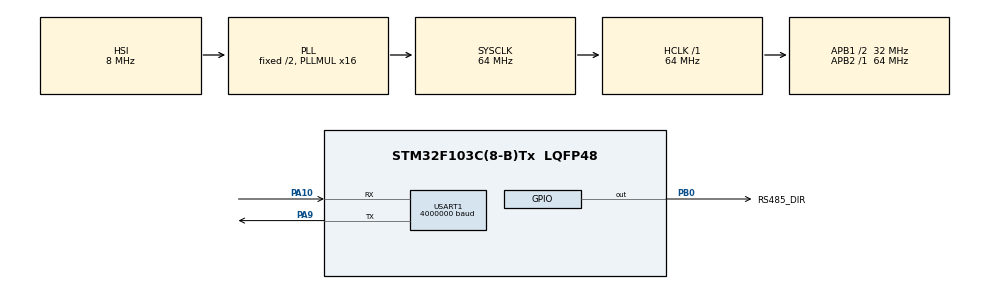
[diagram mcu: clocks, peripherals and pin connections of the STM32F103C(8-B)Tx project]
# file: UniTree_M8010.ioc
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Dma.Request0=USART1_RX
Dma.Request1=USART1_TX
Dma.USART1_RX.0.Direction=DMA_PERIPH_TO_MEMORY
Dma.USART1_RX.0.Instance=DMA1_Channel5
Dma.USART1_RX.0.MemDataAlignment=DMA_MDATAALIGN_BYTE
Dma.USART1_RX.0.MemInc=DMA_MINC_ENABLE
Dma.USART1_RX.0.Mode=DMA_NORMAL
Dma.USART1_RX.0.PeriphDataAlignment=DMA_PDATAALIGN_BYTE
Dma.USART1_RX.0.PeriphInc=DMA_PINC_DISABLE
Dma.USART1_RX.0.Priority=DMA_PRIORITY_LOW
Dma.USART1_TX.1.Direction=DMA_MEMORY_TO_PERIPH
Dma.USART1_TX.1.Instance=DMA1_Channel4
Dma.USART1_TX.1.MemDataAlignment=DMA_MDATAALIGN_BYTE
Dma.USART1_TX.1.MemInc=DMA_MINC_ENABLE
Dma.USART1_TX.1.Mode=DMA_NORMAL
Dma.USART1_TX.1.PeriphDataAlignment=DMA_PDATAALIGN_BYTE
Dma.USART1_TX.1.PeriphInc=DMA_PINC_DISABLE
Dma.USART1_TX.1.Priority=DMA_PRIORITY_LOW
Mcu.Family=STM32F1
Mcu.Name=STM32F103C(8-B)Tx
Mcu.Package=LQFP48
NVIC.DMA1_Channel4_IRQn=true\:0\:0\:false\:false\:true\:false\:true\:true
NVIC.DMA1_Channel5_IRQn=true\:0\:0\:false\:false\:true\:false\:true\:true
NVIC.PriorityGroup=NVIC_PRIORITYGROUP_4
NVIC.USART1_IRQn=true\:0\:0\:false\:false\:true\:true\:true\:true
PA10.Mode=Asynchronous
PA10.Signal=USART1_RX
PA13.Mode=Serial_Wire
PA13.Signal=SYS_JTMS-SWDIO
PA14.Mode=Serial_Wire
PA14.Signal=SYS_JTCK-SWCLK
PA9.Mode=Asynchronous
PA9.Signal=USART1_TX
PB0.GPIO_Label=RS485_DIR
PB0.Signal=GPIO_Output
ProjectManager.HeapSize=0x200
ProjectManager.StackSize=0x400
ProjectManager.TargetToolchain=CMake
RCC.AHBFreq_Value=64000000
RCC.APB1CLKDivider=RCC_HCLK_DIV2
RCC.APB1Freq_Value=32000000
RCC.APB1TimFreq_Value=64000000
RCC.APB2Freq_Value=64000000
RCC.HCLKFreq_Value=64000000
RCC.PLLMul=RCC_PLL_MUL16
RCC.PLLSourceVirtual=RCC_PLLSOURCE_HSI_DIV2
RCC.SYSCLKFreq_VALUE=64000000
RCC.SYSCLKSource=RCC_SYSCLKSOURCE_PLLCLK
USART1.BaudRate=4000000
USART1.VirtualMode=VM_ASYNC
board=custom

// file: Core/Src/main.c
/* USER CODE BEGIN Header */
/**
  ******************************************************************************
  * @file           : main.c
  * @brief          : Main program body
  ******************************************************************************
  * @attention
  *
  * Copyright (c) 2026 STMicroelectronics.
  * All rights reserved.
  *
  * This software is licensed under terms that can be found in the LICENSE file
  * in the root directory of this software component.
  * If no LICENSE file comes with this software, it is provided AS-IS.
  *
  ******************************************************************************
  */
/* USER CODE END Header */
#include "main.h"

/* USER CODE BEGIN Includes */
#include "m8010_motor_manager.h"
/* USER CODE END Includes */

/* USER CODE BEGIN PD */
#define M8010_MOTOR_ID          0U
/* USER CODE END PD */

UART_HandleTypeDef huart1;
DMA_HandleTypeDef hdma_usart1_rx;
DMA_HandleTypeDef hdma_usart1_tx;

/* USER CODE BEGIN PV */
static M8010_MotorManager_t m8010_manager;
static M8010_Motor_t m8010_motor;
/* USER CODE END PV */

void SystemClock_Config(void);
static void MX_GPIO_Init(void);
static void MX_DMA_Init(void);
static void MX_USART1_UART_Init(void);

int main(void)
{

  /* MCU Configuration--------------------------------------------------------*/

  /* Reset of all peripherals, Initializes the Flash interface and the Systick. */
  HAL_Init();

  /* Configure the system clock */
  SystemClock_Config();

  /* Initialize all configured peripherals */
  MX_GPIO_Init();
  MX_DMA_Init();
  MX_USART1_UART_Init();
  /* USER CODE BEGIN 2 */
  if ((M8010_MotorManager_Init(&m8010_manager,
                                &huart1,
                                RS485_DIR_GPIO_Port,
                                RS485_DIR_Pin) != HAL_OK) ||
      (M8010_MotorManager_Register(&m8010_manager,
                                    &m8010_motor,
                                    M8010_MOTOR_ID) != HAL_OK))
  {
    Error_Handler();
  }
  uint32_t now = HAL_GetTick();

  /* USER CODE END 2 */

  /* Infinite loop */
  /* USER CODE BEGIN WHILE */
  while (1)
  {
    if (HAL_GetTick() - now > 1U)
    {
      now = HAL_GetTick();
      (void)M8010_MotorManager_Update(&m8010_manager, HAL_GetTick());
    }
    /* USER CODE END WHILE */

  }
}

void SystemClock_Config(void)
{
  RCC_OscInitTypeDef RCC_OscInitStruct = {0};
  RCC_ClkInitTypeDef RCC_ClkInitStruct = {0};

  /** Initializes the RCC Oscillators according to the specified parameters
  * in the RCC_OscInitTypeDef structure.
  */
  RCC_OscInitStruct.OscillatorType = RCC_OSCILLATORTYPE_HSI;
  RCC_OscInitStruct.HSIState = RCC_HSI_ON;
  RCC_OscInitStruct.HSICalibrationValue = RCC_HSICALIBRATION_DEFAULT;
  RCC_OscInitStruct.PLL.PLLState = RCC_PLL_ON;
  RCC_OscInitStruct.PLL.PLLSource = RCC_PLLSOURCE_HSI_DIV2;
  RCC_OscInitStruct.PLL.PLLMUL = RCC_PLL_MUL16;
  if (HAL_RCC_OscConfig(&RCC_OscInitStruct) != HAL_OK)
  {
    Error_Handler();
  }

  /** Initializes the CPU, AHB and APB buses clocks
  */
  RCC_ClkInitStruct.ClockType = RCC_CLOCKTYPE_HCLK|RCC_CLOCKTYPE_SYSCLK
                              |RCC_CLOCKTYPE_PCLK1|RCC_CLOCKTYPE_PCLK2;
  RCC_ClkInitStruct.SYSCLKSource = RCC_SYSCLKSOURCE_PLLCLK;
  RCC_ClkInitStruct.AHBCLKDivider = RCC_SYSCLK_DIV1;
  RCC_ClkInitStruct.APB1CLKDivider = RCC_HCLK_DIV2;
  RCC_ClkInitStruct.APB2CLKDivider = RCC_HCLK_DIV1;

  if (HAL_RCC_ClockConfig(&RCC_ClkInitStruct, FLASH_LATENCY_2) != HAL_OK)
  {
    Error_Handler();
  }
}

static void MX_USART1_UART_Init(void)
{

  huart1.Instance = USART1;
  huart1.Init.BaudRate = 4000000;
  huart1.Init.WordLength = UART_WORDLENGTH_8B;
  huart1.Init.StopBits = UART_STOPBITS_1;
  huart1.Init.Parity = UART_PARITY_NONE;
  huart1.Init.Mode = UART_MODE_TX_RX;
  huart1.Init.HwFlowCtl = UART_HWCONTROL_NONE;
  huart1.Init.OverSampling = UART_OVERSAMPLING_16;
  if (HAL_UART_Init(&huart1) != HAL_OK)
  {
    Error_Handler();
  }

}

static void MX_DMA_Init(void)
{

  /* DMA controller clock enable */
  __HAL_RCC_DMA1_CLK_ENABLE();

  /* DMA interrupt init */
  /* DMA1_Channel4_IRQn interrupt configuration */
  HAL_NVIC_SetPriority(DMA1_Channel4_IRQn, 0, 0);
  HAL_NVIC_EnableIRQ(DMA1_Channel4_IRQn);
  /* DMA1_Channel5_IRQn interrupt configuration */
  HAL_NVIC_SetPriority(DMA1_Channel5_IRQn, 0, 0);
  HAL_NVIC_EnableIRQ(DMA1_Channel5_IRQn);

}

static void MX_GPIO_Init(void)
{
  GPIO_InitTypeDef GPIO_InitStruct = {0};

  /* GPIO Ports Clock Enable */
  __HAL_RCC_GPIOA_CLK_ENABLE();
  __HAL_RCC_GPIOB_CLK_ENABLE();

  /*Configure GPIO pin Output Level */
  HAL_GPIO_WritePin(RS485_DIR_GPIO_Port, RS485_DIR_Pin, GPIO_PIN_RESET);

  /*Configure GPIO pin : RS485_DIR_Pin */
  GPIO_InitStruct.Pin = RS485_DIR_Pin;
  GPIO_InitStruct.Mode = GPIO_MODE_OUTPUT_PP;
  GPIO_InitStruct.Speed = GPIO_SPEED_FREQ_HIGH;
  HAL_GPIO_Init(RS485_DIR_GPIO_Port, &GPIO_InitStruct);

}

/* USER CODE BEGIN 4 */
void HAL_UART_TxCpltCallback(UART_HandleTypeDef *huart)
{
  if (huart == m8010_manager.huart)
  {
    M8010_MotorManager_TxCallBack(&m8010_manager);
  }
}

void HAL_UART_RxCpltCallback(UART_HandleTypeDef *huart)
{
  if (huart == m8010_manager.huart)
  {
    M8010_MotorManager_RxCallBack(&m8010_manager);
  }
}

void HAL_UART_ErrorCallback(UART_HandleTypeDef *huart)
{
  if (huart == m8010_manager.huart)
  {
    M8010_MotorManager_ErrorCallBack(&m8010_manager);
  }
}

/* USER CODE END 4 */

void Error_Handler(void)
{
  __disable_irq();
  while (1)
  {
  }
}
